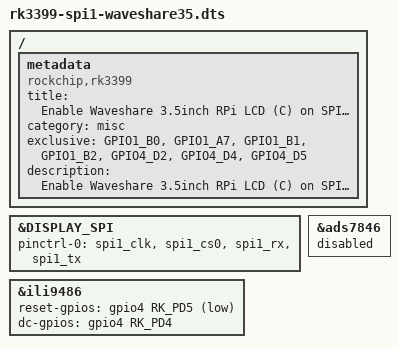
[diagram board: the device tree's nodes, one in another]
#define DISPLAY_SPI spi1
#include "waveshare35-lcd.dtsi"

/ {
	metadata {
		title = "Enable Waveshare 3.5inch RPi LCD (C) on SPI1 (No Touch Support)";
		compatible = "rockchip,rk3399";
		category = "misc";
		exclusive = "GPIO1_B0", "GPIO1_A7", "GPIO1_B1", "GPIO1_B2", "GPIO4_D2", "GPIO4_D4", "GPIO4_D5" ;
		description = "Enable Waveshare 3.5inch RPi LCD (C) on SPI1 (No Touch Support).
Due to hardware conflict, touch is not available when using with ROCK 4.";
	};
};

&DISPLAY_SPI {
	pinctrl-0 = <&spi1_clk &spi1_cs0 &spi1_rx &spi1_tx>;
};

&ili9486 {
	reset-gpios = <&gpio4 RK_PD5 GPIO_ACTIVE_LOW>;
	dc-gpios = <&gpio4 RK_PD4 GPIO_ACTIVE_HIGH>;
};

&ads7846 {
	status = "disabled";
};
